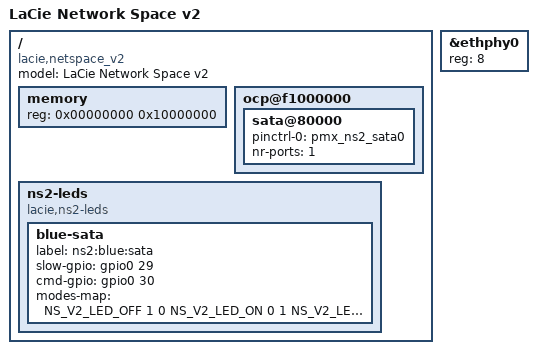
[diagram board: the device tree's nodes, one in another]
/dts-v1/;

#include <dt-bindings/leds/leds-ns2.h>
#include "kirkwood-ns2-common.dtsi"

/ {
	model = "LaCie Network Space v2";
	compatible = "lacie,netspace_v2", "marvell,kirkwood-88f6281", "marvell,kirkwood";

	memory {
		device_type = "memory";
		reg = <0x00000000 0x10000000>;
	};

	ocp@f1000000 {
		sata@80000 {
			pinctrl-0 = <&pmx_ns2_sata0>;
			pinctrl-names = "default";
			status = "okay";
			nr-ports = <1>;
		};
	};

	ns2-leds {
		compatible = "lacie,ns2-leds";

		blue-sata {
			label = "ns2:blue:sata";
			slow-gpio = <&gpio0 29 0>;
			cmd-gpio = <&gpio0 30 0>;
			modes-map = <NS_V2_LED_OFF  1 0
				     NS_V2_LED_ON   0 1
				     NS_V2_LED_ON   1 1
				     NS_V2_LED_SATA 0 0>;
		};
	};
};

&ethphy0 { reg = <8>; };
